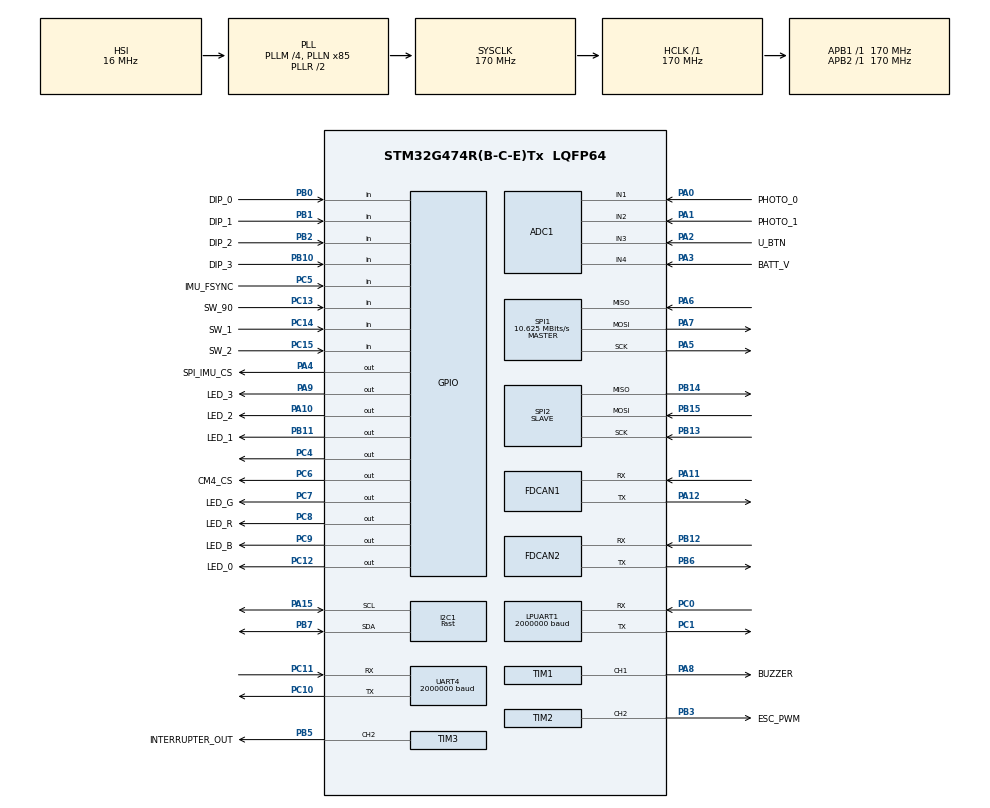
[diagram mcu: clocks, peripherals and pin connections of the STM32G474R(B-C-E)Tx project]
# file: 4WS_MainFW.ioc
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ADC1.Channel-0\#ChannelRegularConversion=ADC_CHANNEL_3
ADC1.ContinuousConvMode=ENABLE
ADC1.DMAContinuousRequests=ENABLE
ADC1.NbrOfConversionFlag=1
ADC1.OffsetNumber-0\#ChannelRegularConversion=ADC_OFFSET_NONE
ADC1.OversamplingMode=ENABLE
ADC1.Rank-0\#ChannelRegularConversion=1
ADC1.Ratio=ADC_OVERSAMPLING_RATIO_4
ADC1.RightBitShift=ADC_RIGHTBITSHIFT_2
ADC1.SamplingTime-0\#ChannelRegularConversion=ADC_SAMPLETIME_640CYCLES_5
ADC1.master=1
FDCAN1.AutoRetransmission=ENABLE
FDCAN1.CalculateBaudRateNominal=1000000
FDCAN1.CalculateTimeBitNominal=1000
FDCAN1.CalculateTimeQuantumNominal=58.8235294117647
FDCAN1.ClockDivider=FDCAN_CLOCK_DIV1
FDCAN1.DataTimeSeg1=1
FDCAN1.DataTimeSeg2=1
FDCAN1.FrameFormat=FDCAN_FRAME_CLASSIC
FDCAN1.NominalPrescaler=10
FDCAN1.NominalTimeSeg1=14
FDCAN1.NominalTimeSeg2=2
FDCAN1.StdFiltersNbr=1
FDCAN2.AutoRetransmission=ENABLE
FDCAN2.CalculateBaudRateNominal=1000000
FDCAN2.CalculateTimeBitNominal=1000
FDCAN2.CalculateTimeQuantumNominal=58.8235294117647
FDCAN2.FrameFormat=FDCAN_FRAME_CLASSIC
FDCAN2.NominalPrescaler=10
FDCAN2.NominalTimeSeg1=14
FDCAN2.NominalTimeSeg2=2
FDCAN2.StdFiltersNbr=1
I2C1.I2C_Speed_Mode=I2C_Fast
I2C1.Timing=0x60400D28
LPUART1.BaudRate=2000000
Mcu.Family=STM32G4
Mcu.Name=STM32G474R(B-C-E)Tx
Mcu.Package=LQFP64
NVIC.PriorityGroup=NVIC_PRIORITYGROUP_4
PA0.GPIO_Label=PHOTO_0
PA0.Mode=IN1-Single-Ended
PA0.Signal=ADC1_IN1
PA1.GPIO_Label=PHOTO_1
PA1.Mode=IN2-Single-Ended
PA1.Signal=ADC1_IN2
PA10.GPIO_Label=LED_2
PA10.Signal=GPIO_Output
PA11.Mode=FDCAN_Activate
PA11.Signal=FDCAN1_RX
PA12.Mode=FDCAN_Activate
PA12.Signal=FDCAN1_TX
PA13.Mode=Serial_Wire
PA13.Signal=SYS_JTMS-SWDIO
PA14.Mode=Serial_Wire
PA14.Signal=SYS_JTCK-SWCLK
PA2.GPIO_Label=U_BTN
PA2.Mode=IN3-Single-Ended
PA2.Signal=ADC1_IN3
PA3.GPIO_Label=BATT_V
PA3.Mode=IN4-Single-Ended
PA3.Signal=ADC1_IN4
PA4.GPIO_Label=SPI_IMU_CS
PA4.Signal=GPIO_Output
PA5.Mode=Full_Duplex_Master
PA5.Signal=SPI1_SCK
PA6.Mode=Full_Duplex_Master
PA6.Signal=SPI1_MISO
PA7.Mode=Full_Duplex_Master
PA7.Signal=SPI1_MOSI
PA8.GPIO_Label=BUZZER
PA8.Signal=S_TIM1_CH1
PA9.GPIO_Label=LED_3
PA9.Signal=GPIO_Output
PB0.GPIO_Label=DIP_0
PB0.Signal=GPIO_Input
PB1.GPIO_Label=DIP_1
PB1.Signal=GPIO_Input
PB10.GPIO_Label=DIP_3
PB10.Signal=GPIO_Input
PB11.GPIO_Label=LED_1
PB11.Signal=GPIO_Output
PB12.Mode=FDCAN_Activate
PB12.Signal=FDCAN2_RX
PB13.Mode=Full_Duplex_Slave
PB13.Signal=SPI2_SCK
PB14.Mode=Full_Duplex_Slave
PB14.Signal=SPI2_MISO
PB15.Mode=Full_Duplex_Slave
PB15.Signal=SPI2_MOSI
PB2.GPIO_Label=DIP_2
PB2.Signal=GPIO_Input
PB3.GPIO_Label=ESC_PWM
PB3.Signal=S_TIM2_CH2
PB5.GPIO_Label=INTERRUPTER_OUT
PB5.Signal=S_TIM3_CH2
PB6.Mode=FDCAN_Activate
PB6.Signal=FDCAN2_TX
PB7.Mode=I2C
PB7.Signal=I2C1_SDA
PA15.Mode=I2C
PA15.Signal=I2C1_SCL
PC0.Mode=Asynchronous
PC0.Signal=LPUART1_RX
PC1.Mode=Asynchronous
PC1.Signal=LPUART1_TX
PC10.Mode=Asynchronous
PC10.Signal=UART4_TX
PC11.Mode=Asynchronous
PC11.Signal=UART4_RX
PC12.GPIO_Label=LED_0
PC12.Signal=GPIO_Output
PC13.GPIO_PuPd=GPIO_PULLUP
PC13.GPIO_Label=SW_90
PC13.Signal=GPIO_Input
PC14-OSC32_IN.GPIO_Label=SW_1
PC14-OSC32_IN.GPIO_PuPd=GPIO_PULLUP
PC14-OSC32_IN.Signal=GPIO_Input
PC15-OSC32_OUT.GPIO_PuPd=GPIO_PULLUP
PC15-OSC32_OUT.GPIO_Label=SW_2
PC15-OSC32_OUT.Signal=GPIO_Input
PC4.Signal=GPIO_Output
PC5.GPIO_Label=IMU_FSYNC
PC5.Signal=GPIO_Input
PC6.GPIO_Label=CM4_CS
PC6.Signal=GPIO_Output
PC7.GPIO_Label=LED_G
PC7.Signal=GPIO_Output
PC8.GPIO_Label=LED_R
PC8.Signal=GPIO_Output
PC9.GPIO_Label=LED_B
PC9.Signal=GPIO_Output
PF0-OSC_IN.Mode=HSE-External-Oscillator
PF0-OSC_IN.Signal=RCC_OSC_IN
PF1-OSC_OUT.Mode=HSE-External-Oscillator
PF1-OSC_OUT.Signal=RCC_OSC_OUT
ProjectManager.HeapSize=0x200
ProjectManager.StackSize=0x400
ProjectManager.TargetToolchain=CMake
RCC.ADC12Freq_Value=170000000
RCC.ADC345Freq_Value=170000000
RCC.AHBFreq_Value=170000000
RCC.APB1Freq_Value=170000000
RCC.APB1TimFreq_Value=170000000
RCC.APB2Freq_Value=170000000
RCC.APB2TimFreq_Value=170000000
RCC.CortexFreq_Value=170000000
RCC.EXTERNAL_CLOCK_VALUE=12288000
RCC.HCLKFreq_Value=170000000
RCC.HSE_VALUE=8000000
RCC.HSI48_VALUE=48000000
RCC.HSI_VALUE=16000000
RCC.LSE_VALUE=32768
RCC.PLLM=RCC_PLLM_DIV4
RCC.PLLN=85
RCC.SYSCLKFreq_VALUE=170000000
RCC.SYSCLKSource=RCC_SYSCLKSOURCE_PLLCLK
RCC.USBFreq_Value=170000000
RCC.VCOOutputFreq_Value=340000000
SH.S_TIM1_CH1.0=TIM1_CH1,PWM Generation1 CH1
SH.S_TIM2_CH2.0=TIM2_CH2,PWM Generation2 CH2
SH.S_TIM3_CH2.0=TIM3_CH2,PWM Generation2 CH2
SPI1.BaudRatePrescaler=SPI_BAUDRATEPRESCALER_16
SPI1.CalculateBaudRate=10.625 MBits/s
SPI1.DataSize=SPI_DATASIZE_8BIT
SPI1.Direction=SPI_DIRECTION_2LINES
SPI1.Mode=SPI_MODE_MASTER
SPI1.VirtualType=VM_MASTER
SPI2.DataSize=SPI_DATASIZE_8BIT
SPI2.Direction=SPI_DIRECTION_2LINES
SPI2.Mode=SPI_MODE_SLAVE
SPI2.VirtualType=VM_SLAVE
TIM1.Channel-PWM\ Generation1\ CH1=TIM_CHANNEL_1
TIM1.Prescaler=16
TIM2.Channel-PWM\ Generation2\ CH2=TIM_CHANNEL_2
TIM2.PeriodNoDither=1000
TIM2.Prescaler=170
TIM3.Channel-PWM\ Generation2\ CH2=TIM_CHANNEL_2
UART4.BaudRate=2000000
VP_CORDIC_VS_CORDIC.Mode=CORDIC_Activate
VP_SYS_VS_DBSignals.Mode=DisableDeadBatterySignals
board=custom

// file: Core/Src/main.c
/* USER CODE BEGIN Header */
/**
  ******************************************************************************
  * @file           : main.c
  * @brief          : Main program body
  ******************************************************************************
  * @attention
  *
  * Copyright (c) 2026 STMicroelectronics.
  * All rights reserved.
  *
  * This software is licensed under terms that can be found in the LICENSE file
  * in the root directory of this software component.
  * If no LICENSE file comes with this software, it is provided AS-IS.
  *
  ******************************************************************************
  */
/* USER CODE END Header */
#include "main.h"
#include "adc.h"
#include "cordic.h"
#include "fdcan.h"
#include "i2c.h"
#include "usart.h"
#include "spi.h"
#include "tim.h"
#include "gpio.h"

/* USER CODE BEGIN Includes */
#include "App/app.h"

/* USER CODE END Includes */

void SystemClock_Config(void);

int main(void)
{

  /* MCU Configuration--------------------------------------------------------*/

  /* Reset of all peripherals, Initializes the Flash interface and the Systick. */
  HAL_Init();

  /* Configure the system clock */
  SystemClock_Config();

  /* Initialize all configured peripherals */
  MX_GPIO_Init();
  MX_ADC1_Init();
  MX_FDCAN1_Init();
  MX_FDCAN2_Init();
  MX_I2C1_Init();
  MX_LPUART1_UART_Init();
  MX_UART4_Init();
  MX_SPI1_Init();
  MX_SPI2_Init();
  MX_TIM1_Init();
  MX_TIM2_Init();
  MX_TIM3_Init();
  MX_CORDIC_Init();
  /* USER CODE BEGIN 2 */
  /* 全周辺初期化後に基礎ドライバを開始する。出力操作はAppの明示要求に限定する。 */
  if (!app_init()) { Error_Handler(); }

  /* USER CODE END 2 */

  /* Infinite loop */
  while (1)
  {

    /* USER CODE BEGIN 3 */
    app_process();
  }
  /* USER CODE END 3 */
}

void SystemClock_Config(void)
{
  RCC_OscInitTypeDef RCC_OscInitStruct = {0};
  RCC_ClkInitTypeDef RCC_ClkInitStruct = {0};

  /** Configure the main internal regulator output voltage
  */
  HAL_PWREx_ControlVoltageScaling(PWR_REGULATOR_VOLTAGE_SCALE1_BOOST);

  /** Initializes the RCC Oscillators according to the specified parameters
  * in the RCC_OscInitTypeDef structure.
  */
  RCC_OscInitStruct.OscillatorType = RCC_OSCILLATORTYPE_HSI;
  RCC_OscInitStruct.HSIState = RCC_HSI_ON;
  RCC_OscInitStruct.HSICalibrationValue = RCC_HSICALIBRATION_DEFAULT;
  RCC_OscInitStruct.PLL.PLLState = RCC_PLL_ON;
  RCC_OscInitStruct.PLL.PLLSource = RCC_PLLSOURCE_HSI;
  RCC_OscInitStruct.PLL.PLLM = RCC_PLLM_DIV4;
  RCC_OscInitStruct.PLL.PLLN = 85;
  RCC_OscInitStruct.PLL.PLLP = RCC_PLLP_DIV2;
  RCC_OscInitStruct.PLL.PLLQ = RCC_PLLQ_DIV2;
  RCC_OscInitStruct.PLL.PLLR = RCC_PLLR_DIV2;
  if (HAL_RCC_OscConfig(&RCC_OscInitStruct) != HAL_OK)
  {
    Error_Handler();
  }

  /** Initializes the CPU, AHB and APB buses clocks
  */
  RCC_ClkInitStruct.ClockType = RCC_CLOCKTYPE_HCLK|RCC_CLOCKTYPE_SYSCLK
                              |RCC_CLOCKTYPE_PCLK1|RCC_CLOCKTYPE_PCLK2;
  RCC_ClkInitStruct.SYSCLKSource = RCC_SYSCLKSOURCE_PLLCLK;
  RCC_ClkInitStruct.AHBCLKDivider = RCC_SYSCLK_DIV1;
  RCC_ClkInitStruct.APB1CLKDivider = RCC_HCLK_DIV1;
  RCC_ClkInitStruct.APB2CLKDivider = RCC_HCLK_DIV1;

  if (HAL_RCC_ClockConfig(&RCC_ClkInitStruct, FLASH_LATENCY_4) != HAL_OK)
  {
    Error_Handler();
  }
}

void Error_Handler(void)
{
  __disable_irq();
  while (1)
  {
  }
}
